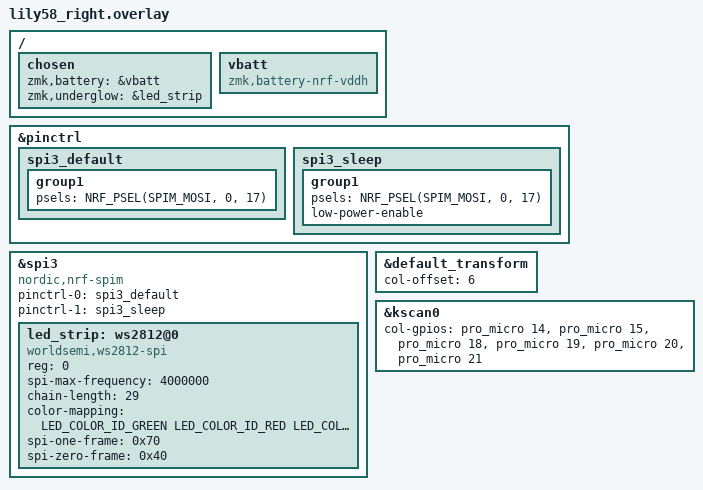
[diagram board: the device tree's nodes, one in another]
#include "lily58.dtsi"
#include <dt-bindings/led/led.h>

/* --- WS2812 on nRF52840 SPI3 MOSI = P0.06 --- */
&pinctrl {
	spi3_default: spi3_default {
		group1 { psels = <NRF_PSEL(SPIM_MOSI, 0, 17)>; };
	};
	spi3_sleep: spi3_sleep {
		group1 { psels = <NRF_PSEL(SPIM_MOSI, 0, 17)>; low-power-enable; };
	};
};


&spi3 {
	compatible = "nordic,nrf-spim";
	status = "okay";
	pinctrl-0 = <&spi3_default>;
	pinctrl-1 = <&spi3_sleep>;
	pinctrl-names = "default", "sleep";

	led_strip: ws2812@0 {
		compatible = "worldsemi,ws2812-spi";
		reg = <0>;
		spi-max-frequency = <4000000>;
		chain-length = <29>;                 /* <-- set to your RIGHT half LED count */
		color-mapping = <LED_COLOR_ID_GREEN LED_COLOR_ID_RED LED_COLOR_ID_BLUE>;
		spi-one-frame = <0x70>;
		spi-zero-frame = <0x40>;
	};
};

/* --- Logical transform: right half starts at col 6 --- */
&default_transform {
	col-offset = <6>;
};

/* --- Matrix: columns for RIGHT half --- */
&kscan0 {
	col-gpios =
			<&pro_micro 14 GPIO_ACTIVE_HIGH>,
			<&pro_micro 15 GPIO_ACTIVE_HIGH>,
			<&pro_micro 18 GPIO_ACTIVE_HIGH>,
			<&pro_micro 19 GPIO_ACTIVE_HIGH>,
			<&pro_micro 20 GPIO_ACTIVE_HIGH>,
			<&pro_micro 21 GPIO_ACTIVE_HIGH>;
};

/* --- Battery + Underglow selection --- */
/ {
	chosen {
		zmk,battery = &vbatt;
		zmk,underglow = &led_strip;
	};

	vbatt: vbatt {
		compatible = "zmk,battery-nrf-vddh";
	};
};
